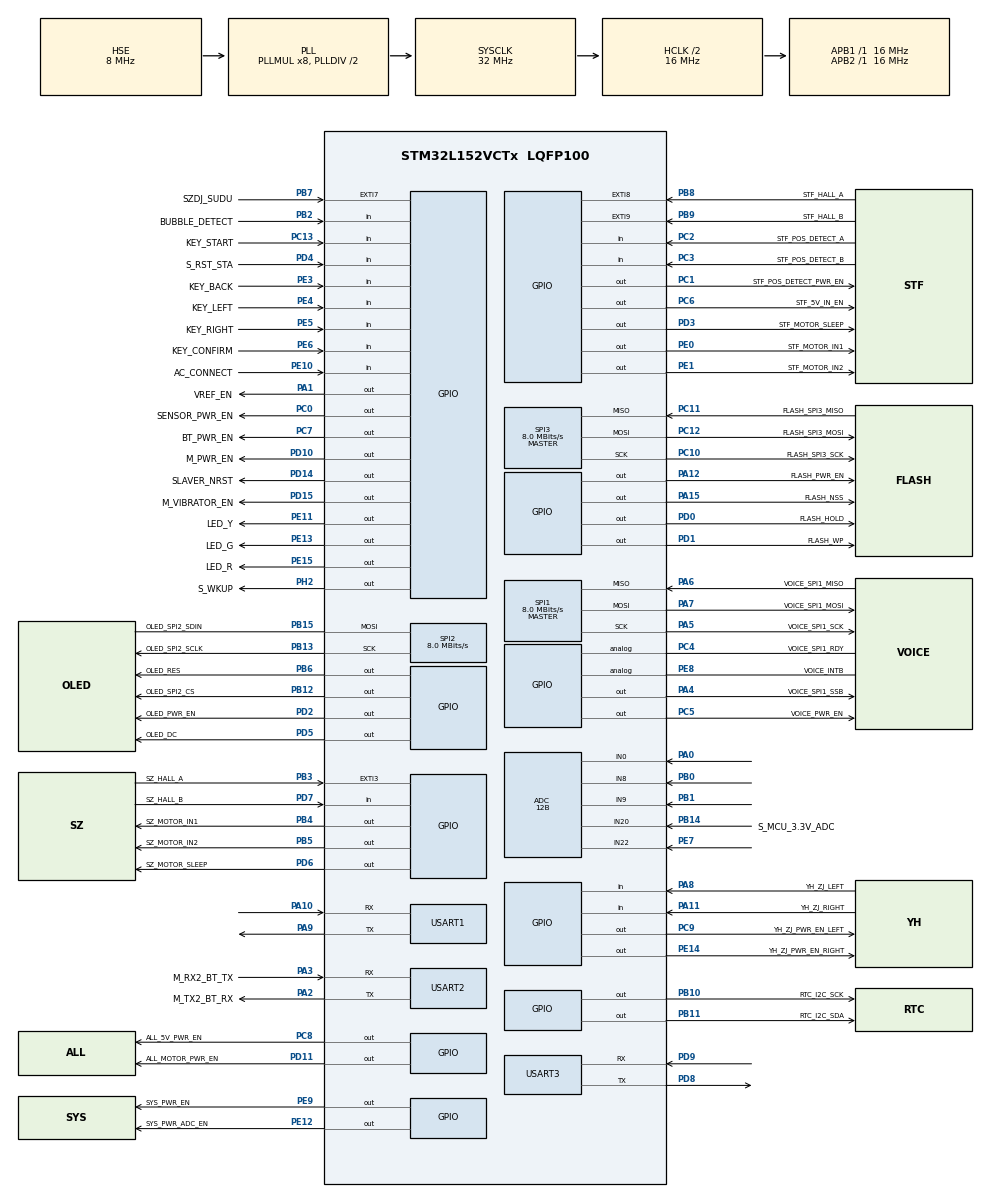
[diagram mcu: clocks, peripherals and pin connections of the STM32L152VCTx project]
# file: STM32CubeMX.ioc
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ADC.Channel-0\#ChannelRegularConversion=ADC_CHANNEL_0
ADC.ClockPrescaler=ADC_CLOCK_ASYNC_DIV1
ADC.ContinuousConvMode=DISABLE
ADC.DMAContinuousRequests=DISABLE
ADC.DataAlign=ADC_DATAALIGN_RIGHT
ADC.DiscontinuousConvMode=DISABLE
ADC.EOCSelection=ADC_EOC_SEQ_CONV
ADC.EnableAnalogWatchDog=false
ADC.ExternalTrigConv=ADC_SOFTWARE_START
ADC.ExternalTrigConvEdge=ADC_EXTERNALTRIGCONVEDGE_NONE
ADC.InjNumberOfConversion=0
ADC.LowPowerAutoPowerOff=ADC_AUTOPOWEROFF_IDLE_PHASE
ADC.LowPowerAutoWait=ADC_AUTOWAIT_DISABLE
ADC.NbrOfConversion=1
ADC.NbrOfConversionFlag=1
ADC.Rank-0\#ChannelRegularConversion=1
ADC.Resolution=ADC_RESOLUTION_12B
ADC.SamplingTime-0\#ChannelRegularConversion=ADC_SAMPLETIME_4CYCLES
ADC.ScanConvMode=ADC_SCAN_DISABLE
Mcu.Family=STM32L1
Mcu.Name=STM32L152VCTx
Mcu.Package=LQFP100
NVIC.EXTI3_IRQn=true\:0\:0\:false\:false\:true\:true
NVIC.EXTI9_5_IRQn=true\:0\:0\:false\:false\:true\:true
NVIC.PriorityGroup=NVIC_PRIORITYGROUP_4
NVIC.TIM5_IRQn=true\:0\:0\:true\:false\:true\:true
NVIC.USART1_IRQn=true\:0\:0\:false\:false\:true\:true
NVIC.USART2_IRQn=true\:0\:0\:false\:false\:true\:true
NVIC.USART3_IRQn=true\:0\:0\:false\:false\:true\:true
PA0-WKUP1.GPIO_Mode=GPIO_MODE_ANALOG
PA0-WKUP1.GPIO_PuPd=GPIO_NOPULL
PA0-WKUP1.Mode=IN0
PA0-WKUP1.Signal=ADC_IN0
PA1.GPIO_Label=VREF_EN
PA1.Signal=GPIO_Output
PA10.Mode=Asynchronous
PA10.Signal=USART1_RX
PA11.GPIO_Label=YH_ZJ_RIGHT
PA11.GPIO_PuPd=GPIO_PULLUP
PA11.Signal=GPIO_Input
PA12.GPIO_Label=FLASH_PWR_EN
PA12.Signal=GPIO_Output
PA13.Mode=Serial_Wire
PA13.Signal=SYS_JTMS-SWDIO
PA14.Mode=Serial_Wire
PA14.Signal=SYS_JTCK-SWCLK
PA15.GPIO_Label=FLASH_NSS
PA15.GPIO_ModeDefaultOutputPP=GPIO_MODE_OUTPUT_PP
PA15.GPIO_PuPd=GPIO_NOPULL
PA15.GPIO_Speed=GPIO_SPEED_FREQ_LOW
PA15.PinState=GPIO_PIN_RESET
PA15.Signal=GPIO_Output
PA2.GPIO_Label=M_TX2_BT_RX
PA2.GPIO_Mode=GPIO_MODE_AF_PP
PA2.GPIO_PuPd=GPIO_PULLUP
PA2.GPIO_Speed=GPIO_SPEED_FREQ_VERY_HIGH
PA2.Mode=Asynchronous
PA2.Signal=USART2_TX
PA3.GPIO_Label=M_RX2_BT_TX
PA3.GPIO_Mode=GPIO_MODE_AF_PP
PA3.GPIO_PuPd=GPIO_PULLUP
PA3.GPIO_Speed=GPIO_SPEED_FREQ_VERY_HIGH
PA3.Mode=Asynchronous
PA3.Signal=USART2_RX
PA4.GPIO_Label=VOICE_SPI1_SSB
PA4.Signal=GPIO_Output
PA5.GPIO_Label=VOICE_SPI1_SCK
PA5.Mode=Full_Duplex_Master
PA5.Signal=SPI1_SCK
PA6.GPIO_Label=VOICE_SPI1_MISO
PA6.Mode=Full_Duplex_Master
PA6.Signal=SPI1_MISO
PA7.GPIO_Label=VOICE_SPI1_MOSI
PA7.Mode=Full_Duplex_Master
PA7.Signal=SPI1_MOSI
PA8.GPIO_Label=YH_ZJ_LEFT
PA8.GPIO_PuPd=GPIO_PULLUP
PA8.Signal=GPIO_Input
PA9.Mode=Asynchronous
PA9.Signal=USART1_TX
PB0.GPIO_Mode=GPIO_MODE_ANALOG
PB0.GPIO_PuPd=GPIO_NOPULL
PB0.Mode=IN8
PB0.Signal=ADC_IN8
PB1.GPIO_Mode=GPIO_MODE_ANALOG
PB1.GPIO_PuPd=GPIO_NOPULL
PB1.Mode=IN9
PB1.Signal=ADC_IN9
PB10.GPIO_Label=RTC_I2C_SCK
PB10.GPIO_ModeDefaultOutputPP=GPIO_MODE_OUTPUT_OD
PB10.GPIO_Speed=GPIO_SPEED_FREQ_HIGH
PB10.Signal=GPIO_Output
PB11.GPIO_Label=RTC_I2C_SDA
PB11.GPIO_ModeDefaultOutputPP=GPIO_MODE_OUTPUT_OD
PB11.GPIO_Speed=GPIO_SPEED_FREQ_HIGH
PB11.Signal=GPIO_Output
PB12.GPIO_Label=OLED_SPI2_CS
PB12.Signal=GPIO_Output
PB13.GPIO_Label=OLED_SPI2_SCLK
PB13.Mode=Simplex_Bidirectional_Master
PB13.Signal=SPI2_SCK
PB14.GPIO_Label=S_MCU_3.3V_ADC
PB14.Mode=IN20
PB14.Signal=ADC_IN20
PB15.GPIO_Label=OLED_SPI2_SDIN
PB15.Mode=Simplex_Bidirectional_Master
PB15.Signal=SPI2_MOSI
PB2.GPIO_Label=BUBBLE_DETECT
PB2.Signal=GPIO_Input
PB3.GPIO_Label=SZ_HALL_A
PB3.Signal=GPXTI3
PB4.GPIO_Label=SZ_MOTOR_IN1
PB4.Signal=GPIO_Output
PB5.GPIO_Label=SZ_MOTOR_IN2
PB5.Signal=GPIO_Output
PB6.GPIO_Label=OLED_RES
PB6.Signal=GPIO_Output
PB7.GPIO_Label=SZDJ_SUDU
PB7.GPIO_ModeDefaultEXTI=GPIO_MODE_IT_RISING
PB7.Signal=GPXTI7
PB8.GPIO_Label=STF_HALL_A
PB8.Signal=GPXTI8
PB9.GPIO_Label=STF_HALL_B
PB9.Signal=GPXTI9
PC0.GPIO_Label=SENSOR_PWR_EN
PC0.Signal=GPIO_Output
PC1.GPIO_Label=STF_POS_DETECT_PWR_EN
PC1.Signal=GPIO_Output
PC10.GPIO_Label=FLASH_SPI3_SCK
PC10.Mode=Full_Duplex_Master
PC10.Signal=SPI3_SCK
PC11.GPIO_Label=FLASH_SPI3_MISO
PC11.Mode=Full_Duplex_Master
PC11.Signal=SPI3_MISO
PC12.GPIO_Label=FLASH_SPI3_MOSI
PC12.Mode=Full_Duplex_Master
PC12.Signal=SPI3_MOSI
PC13-WKUP2.GPIO_Label=KEY_START
PC13-WKUP2.GPIO_Mode=GPIO_MODE_INPUT
PC13-WKUP2.GPIO_PuPd=GPIO_NOPULL
PC13-WKUP2.Signal=GPIO_Input
PC14-OSC32_IN.Mode=LSE-External-Oscillator
PC14-OSC32_IN.Signal=RCC_OSC32_IN
PC15-OSC32_OUT.Mode=LSE-External-Oscillator
PC15-OSC32_OUT.Signal=RCC_OSC32_OUT
PC2.GPIO_Label=STF_POS_DETECT_A
PC2.Signal=GPIO_Input
PC3.GPIO_Label=STF_POS_DETECT_B
PC3.Signal=GPIO_Input
PC4.GPIO_Label=VOICE_SPI1_RDY
PC4.Signal=GPIO_Analog
PC5.GPIO_Label=VOICE_PWR_EN
PC5.PinState=GPIO_PIN_SET
PC5.Signal=GPIO_Output
PC6.GPIO_Label=STF_5V_IN_EN
PC6.Signal=GPIO_Output
PC7.GPIO_Label=BT_PWR_EN
PC7.Signal=GPIO_Output
PC8.GPIO_Label=ALL_5V_PWR_EN
PC8.Signal=GPIO_Output
PC9.GPIO_Label=YH_ZJ_PWR_EN_LEFT
PC9.Signal=GPIO_Output
PD0.GPIO_Label=FLASH_HOLD
PD0.GPIO_ModeDefaultOutputPP=GPIO_MODE_OUTPUT_PP
PD0.GPIO_PuPd=GPIO_NOPULL
PD0.GPIO_Speed=GPIO_SPEED_FREQ_LOW
PD0.PinState=GPIO_PIN_RESET
PD0.Signal=GPIO_Output
PD1.GPIO_Label=FLASH_WP
PD1.GPIO_ModeDefaultOutputPP=GPIO_MODE_OUTPUT_PP
PD1.GPIO_PuPd=GPIO_NOPULL
PD1.GPIO_Speed=GPIO_SPEED_FREQ_LOW
PD1.PinState=GPIO_PIN_RESET
PD1.Signal=GPIO_Output
PD10.GPIO_Label=M_PWR_EN
PD10.PinState=GPIO_PIN_SET
PD10.Signal=GPIO_Output
PD11.GPIO_Label=ALL_MOTOR_PWR_EN
PD11.Signal=GPIO_Output
PD14.GPIO_Label=SLAVER_NRST
PD14.PinState=GPIO_PIN_SET
PD14.Signal=GPIO_Output
PD15.GPIO_Label=M_VIBRATOR_EN
PD15.Signal=GPIO_Output
PD2.GPIO_Label=OLED_PWR_EN
PD2.Signal=GPIO_Output
PD3.GPIO_Label=STF_MOTOR_SLEEP
PD3.Signal=GPIO_Output
PD4.GPIO_Label=S_RST_STA
PD4.GPIO_PuPd=GPIO_PULLDOWN
PD4.Signal=GPIO_Input
PD5.GPIO_Label=OLED_DC
PD5.Signal=GPIO_Output
PD6.GPIO_Label=SZ_MOTOR_SLEEP
PD6.Signal=GPIO_Output
PD7.GPIO_Label=SZ_HALL_B
PD7.Signal=GPIO_Input
PD8.GPIO_Mode=GPIO_MODE_AF_PP
PD8.GPIO_PuPd=GPIO_PULLUP
PD8.GPIO_Speed=GPIO_SPEED_FREQ_VERY_HIGH
PD8.Mode=Asynchronous
PD8.Signal=USART3_TX
PD9.GPIO_Mode=GPIO_MODE_AF_PP
PD9.GPIO_PuPd=GPIO_PULLUP
PD9.GPIO_Speed=GPIO_SPEED_FREQ_VERY_HIGH
PD9.Mode=Asynchronous
PD9.Signal=USART3_RX
PE0.GPIO_Label=STF_MOTOR_IN1
PE0.Signal=GPIO_Output
PE1.GPIO_Label=STF_MOTOR_IN2
PE1.Signal=GPIO_Output
PE10.GPIO_Label=AC_CONNECT
PE10.Signal=GPIO_Input
PE11.GPIO_Label=LED_Y
PE11.PinState=GPIO_PIN_RESET
PE11.Signal=GPIO_Output
PE12.GPIO_Label=SYS_PWR_ADC_EN
PE12.Signal=GPIO_Output
PE13.GPIO_Label=LED_G
PE13.PinState=GPIO_PIN_RESET
PE13.Signal=GPIO_Output
PE14.GPIO_Label=YH_ZJ_PWR_EN_RIGHT
PE14.Signal=GPIO_Output
PE15.GPIO_Label=LED_R
PE15.PinState=GPIO_PIN_RESET
PE15.Signal=GPIO_Output
PE3.GPIO_Label=KEY_BACK
PE3.Signal=GPIO_Input
PE4.GPIO_Label=KEY_LEFT
PE4.GPIO_Mode=GPIO_MODE_INPUT
PE4.GPIO_PuPd=GPIO_NOPULL
PE4.Signal=GPIO_Input
PE5.GPIO_Label=KEY_RIGHT
PE5.GPIO_Mode=GPIO_MODE_INPUT
PE5.GPIO_PuPd=GPIO_NOPULL
PE5.Signal=GPIO_Input
PE6-WKUP3.GPIO_Label=KEY_CONFIRM
PE6-WKUP3.GPIO_Mode=GPIO_MODE_INPUT
PE6-WKUP3.GPIO_PuPd=GPIO_NOPULL
PE6-WKUP3.Signal=GPIO_Input
PE7.GPIO_Mode=GPIO_MODE_ANALOG
PE7.GPIO_PuPd=GPIO_NOPULL
PE7.Mode=IN22
PE7.Signal=ADC_IN22
PE8.GPIO_Label=VOICE_INTB
PE8.Signal=GPIO_Analog
PE9.GPIO_Label=SYS_PWR_EN
PE9.Signal=GPIO_Output
PH0-OSC_IN.Mode=HSE-External-Oscillator
PH0-OSC_IN.Signal=RCC_OSC_IN
PH1-OSC_OUT.Mode=HSE-External-Oscillator
PH1-OSC_OUT.Signal=RCC_OSC_OUT
PH2.GPIO_Label=S_WKUP
PH2.Signal=GPIO_Output
ProjectManager.HeapSize=0x200
ProjectManager.StackSize=0x400
ProjectManager.TargetToolchain=EWARM
RCC.48MHZClocksFreq_Value=32000000
RCC.AHBCLKDivider=RCC_SYSCLK_DIV2
RCC.AHBFreq_Value=16000000
RCC.APB1Freq_Value=16000000
RCC.APB1TimFreq_Value=16000000
RCC.APB2Freq_Value=16000000
RCC.APB2TimFreq_Value=16000000
RCC.HCLKFreq_Value=16000000
RCC.HSE_VALUE=8000000
RCC.HSI_VALUE=16000000
RCC.MSIClockRange=RCC_MSIRANGE_2
RCC.MSI_VALUE=262144
RCC.PLLMUL=RCC_PLL_MUL8
RCC.PLLSourceVirtual=RCC_PLLSOURCE_HSE
RCC.SYSCLKFreq_VALUE=32000000
RCC.SYSCLKSource=RCC_SYSCLKSOURCE_PLLCLK
RCC.USBOutput=32000000
RCC.VCOOutputFreq_Value=64000000
SPI1.CLKPhase=SPI_PHASE_2EDGE
SPI1.CLKPolarity=SPI_POLARITY_HIGH
SPI1.CalculateBaudRate=8.0 MBits/s
SPI1.Direction=SPI_DIRECTION_2LINES
SPI1.Mode=SPI_MODE_MASTER
SPI1.VirtualType=VM_MASTER
SPI2.CLKPhase=SPI_PHASE_2EDGE
SPI2.CLKPolarity=SPI_POLARITY_HIGH
SPI2.CalculateBaudRate=8.0 MBits/s
SPI2.Direction=SPI_DIRECTION_1LINE
SPI2.Mode=SPI_MODE_MASTER
SPI2.VirtualType=VM_MASTER
SPI3.CalculateBaudRate=8.0 MBits/s
SPI3.Direction=SPI_DIRECTION_2LINES
SPI3.Mode=SPI_MODE_MASTER
SPI3.VirtualType=VM_MASTER
TIM5.ClockDivision=TIM_CLOCKDIVISION_DIV1
TIM5.Period=65535
TIM5.Prescaler=2
USART1.VirtualMode=VM_ASYNC
USART2.VirtualMode=VM_ASYNC
USART3.VirtualMode=VM_ASYNC
VP_TIM5_VS_ClockSourceINT.Mode=Internal
board=STM32CubeMX

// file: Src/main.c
/**
  ******************************************************************************
  * @file           : main.c
  * @brief          : Main program body
  ******************************************************************************
  ** This notice applies to any and all portions of this file
  * that are not between comment pairs USER CODE BEGIN and
  * USER CODE END. Other portions of this file, whether
  * inserted by the user or by software development tools
  * are owned by their respective copyright owners.
  *
  * COPYRIGHT(c) 2018 STMicroelectronics
  *
  * Redistribution and use in source and binary forms, with or without modification,
  * are permitted provided that the following conditions are met:
  *   1. Redistributions of source code must retain the above copyright notice,
  *      this list of conditions and the following disclaimer.
  *   2. Redistributions in binary form must reproduce the above copyright notice,
  *      this list of conditions and the following disclaimer in the documentation
  *      and/or other materials provided with the distribution.
  *   3. Neither the name of STMicroelectronics nor the names of its contributors
  *      may be used to endorse or promote products derived from this software
  *      without specific prior written permission.
  *
  * THIS SOFTWARE IS PROVIDED BY THE COPYRIGHT HOLDERS AND CONTRIBUTORS "AS IS"
  * AND ANY EXPRESS OR IMPLIED WARRANTIES, INCLUDING, BUT NOT LIMITED TO, THE
  * IMPLIED WARRANTIES OF MERCHANTABILITY AND FITNESS FOR A PARTICULAR PURPOSE ARE
  * DISCLAIMED. IN NO EVENT SHALL THE COPYRIGHT HOLDER OR CONTRIBUTORS BE LIABLE
  * FOR ANY DIRECT, INDIRECT, INCIDENTAL, SPECIAL, EXEMPLARY, OR CONSEQUENTIAL
  * DAMAGES (INCLUDING, BUT NOT LIMITED TO, PROCUREMENT OF SUBSTITUTE GOODS OR
  * SERVICES; LOSS OF USE, DATA, OR PROFITS; OR BUSINESS INTERRUPTION) HOWEVER
  * CAUSED AND ON ANY THEORY OF LIABILITY, WHETHER IN CONTRACT, STRICT LIABILITY,
  * OR TORT (INCLUDING NEGLIGENCE OR OTHERWISE) ARISING IN ANY WAY OUT OF THE USE
  * OF THIS SOFTWARE, EVEN IF ADVISED OF THE POSSIBILITY OF SUCH DAMAGE.
  *
  ******************************************************************************
  */
#include "main.h"
#include "stm32l1xx_hal.h"
#include "adc.h"
#include "spi.h"
#include "tim.h"
#include "usart.h"
#include "gpio.h"

/* USER CODE BEGIN Includes */
#include "init.h"
#include "ssz_common.h"
/* USER CODE END Includes */

/* USER CODE BEGIN PV */
/* Private variables ---------------------------------------------------------*/

/* USER CODE END PV */

void SystemClock_Config(void);

/* USER CODE BEGIN PFP */
/* Private function prototypes -----------------------------------------------*/

/* USER CODE END PFP */

/* USER CODE BEGIN 0 */
void main_run();
/* USER CODE END 0 */

int main(void)
{

  /* MCU Configuration----------------------------------------------------------*/

  /* Reset of all peripherals, Initializes the Flash interface and the Systick. */
  HAL_Init();

  /* Configure the system clock */
  SystemClock_Config();

  /* Initialize all configured peripherals */
  MX_GPIO_Init();
  MX_ADC_Init();
  MX_SPI1_Init();
  MX_SPI2_Init();
  MX_SPI3_Init();
  MX_USART1_UART_Init();
  MX_USART2_UART_Init();
  MX_USART3_UART_Init();
  MX_TIM5_Init();
  /* USER CODE BEGIN 2 */
  main_run();
  /* USER CODE END 2 */

  /* Infinite loop */
  while (1)
  {

  }

}

void SystemClock_Config(void)
{

  RCC_OscInitTypeDef RCC_OscInitStruct;
  RCC_ClkInitTypeDef RCC_ClkInitStruct;

    /**Configure the main internal regulator output voltage
    */
  __HAL_PWR_VOLTAGESCALING_CONFIG(PWR_REGULATOR_VOLTAGE_SCALE1);

    /**Initializes the CPU, AHB and APB busses clocks
    */
  RCC_OscInitStruct.OscillatorType = RCC_OSCILLATORTYPE_HSI|RCC_OSCILLATORTYPE_HSE;
  RCC_OscInitStruct.HSEState = RCC_HSE_ON;
  RCC_OscInitStruct.HSIState = RCC_HSI_ON;
  RCC_OscInitStruct.HSICalibrationValue = 16;
  RCC_OscInitStruct.PLL.PLLState = RCC_PLL_ON;
  RCC_OscInitStruct.PLL.PLLSource = RCC_PLLSOURCE_HSE;
  RCC_OscInitStruct.PLL.PLLMUL = RCC_PLL_MUL8;
  RCC_OscInitStruct.PLL.PLLDIV = RCC_PLL_DIV2;
  if (HAL_RCC_OscConfig(&RCC_OscInitStruct) != HAL_OK)
  {
    _Error_Handler(__FILE__, __LINE__);
  }

    /**Initializes the CPU, AHB and APB busses clocks
    */
  RCC_ClkInitStruct.ClockType = RCC_CLOCKTYPE_HCLK|RCC_CLOCKTYPE_SYSCLK
                              |RCC_CLOCKTYPE_PCLK1|RCC_CLOCKTYPE_PCLK2;
  RCC_ClkInitStruct.SYSCLKSource = RCC_SYSCLKSOURCE_PLLCLK;
  RCC_ClkInitStruct.AHBCLKDivider = RCC_SYSCLK_DIV2;
  RCC_ClkInitStruct.APB1CLKDivider = RCC_HCLK_DIV1;
  RCC_ClkInitStruct.APB2CLKDivider = RCC_HCLK_DIV1;

  if (HAL_RCC_ClockConfig(&RCC_ClkInitStruct, FLASH_LATENCY_0) != HAL_OK)
  {
    _Error_Handler(__FILE__, __LINE__);
  }

    /**Configure the Systick interrupt time
    */
  HAL_SYSTICK_Config(HAL_RCC_GetHCLKFreq()/1000);

    /**Configure the Systick
    */
  HAL_SYSTICK_CLKSourceConfig(SYSTICK_CLKSOURCE_HCLK);

  /* SysTick_IRQn interrupt configuration */
  HAL_NVIC_SetPriority(SysTick_IRQn, 0, 0);
}

void _Error_Handler(char *file, int line)
{
  /* USER CODE BEGIN Error_Handler_Debug */
  /* User can add his own implementation to report the HAL error return state */
  #ifdef DEBUG
  ssz_on_check_fail(file, line,"error");
  #else
  ssz_on_check_fail();
  #endif
  while(1)
  {
  }
  /* USER CODE END Error_Handler_Debug */
}

#ifdef  USE_FULL_ASSERT
/**
  * @brief  Reports the name of the source file and the source line number
  *         where the assert_param error has occurred.
  * @param  file: pointer to the source file name
  * @param  line: assert_param error line source number
  * @retval None
  */
void assert_failed(uint8_t* file, uint32_t line)
{
  /* USER CODE BEGIN 6 */
  /* User can add his own implementation to report the file name and line number,
    ex: printf("Wrong parameters value: file %s on line %d\r\n", file, line) */
  ssz_on_assert_fail((char*)file, line,"Wrong parameters value");
  /* USER CODE END 6 */
}
#endif /* USE_FULL_ASSERT */

/************************ (C) COPYRIGHT STMicroelectronics *****END OF FILE****/
